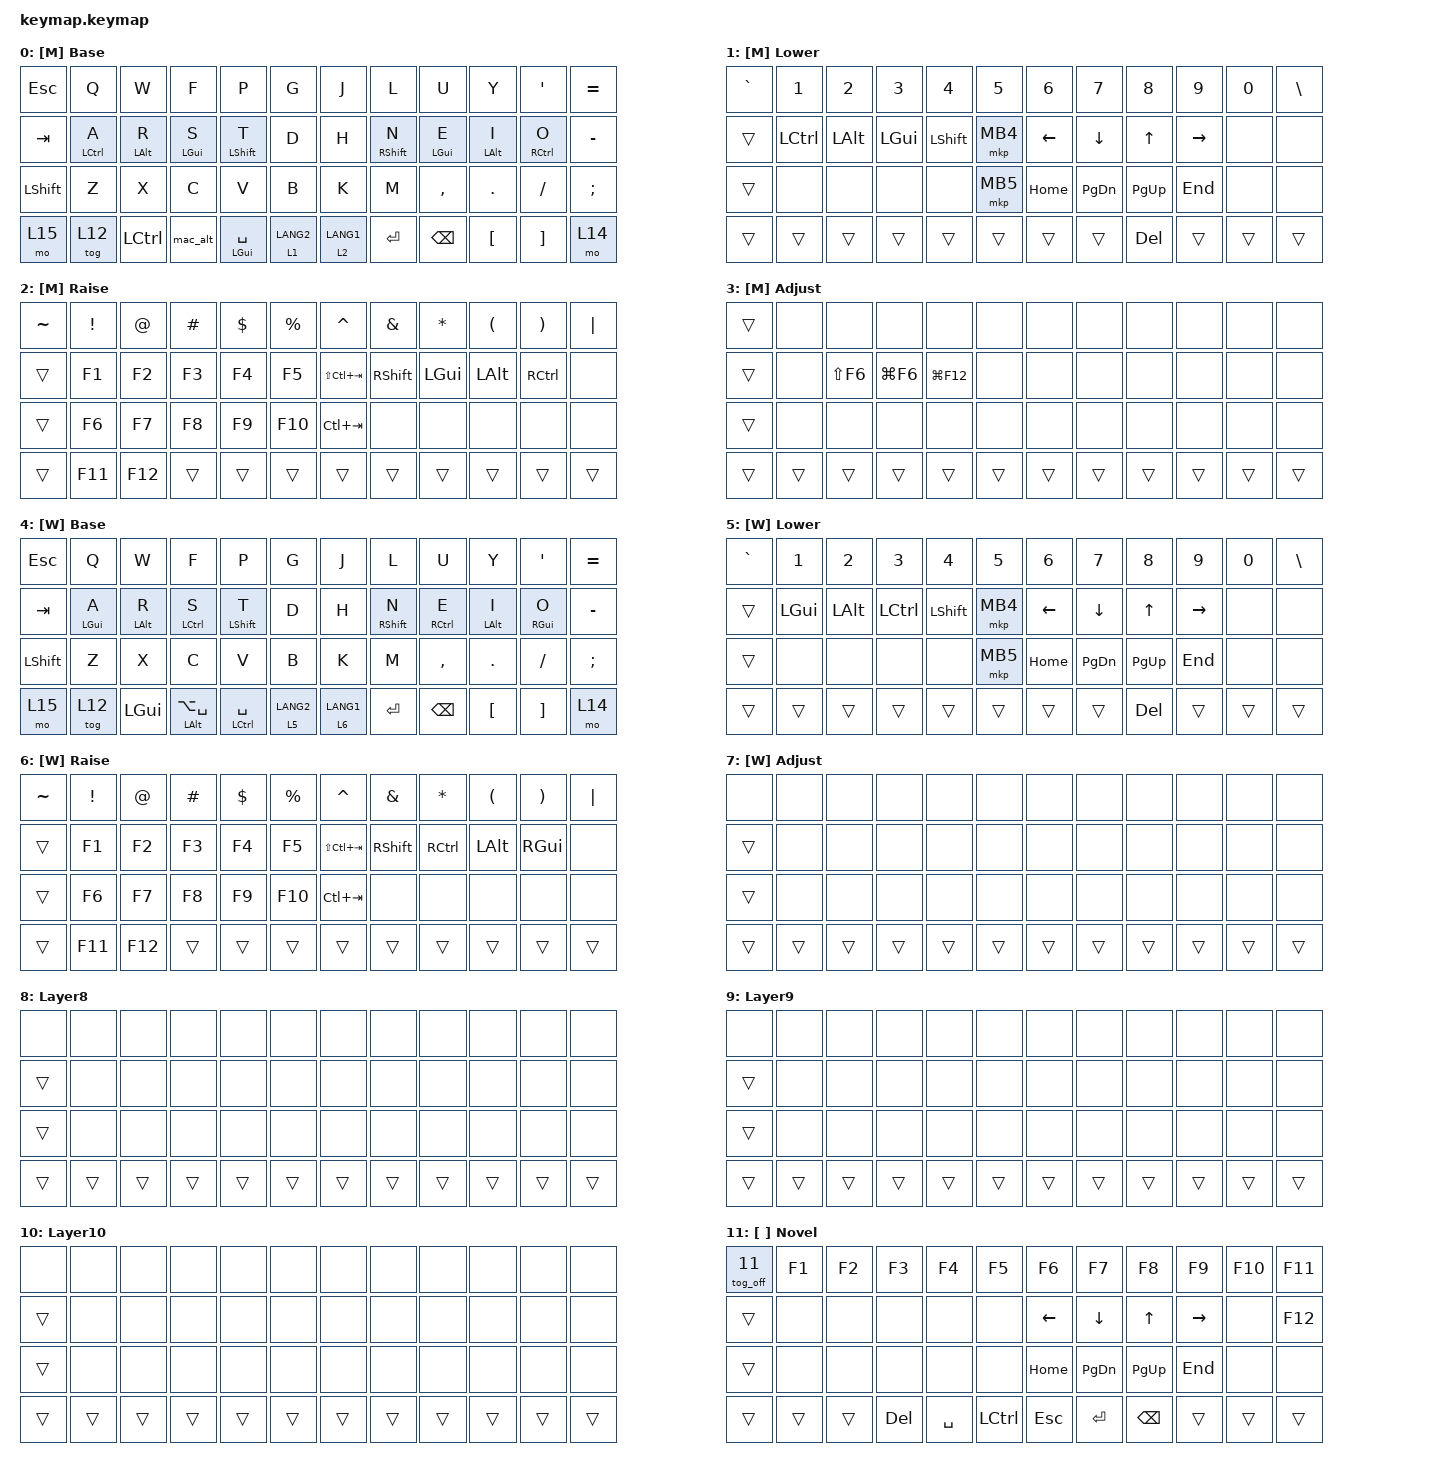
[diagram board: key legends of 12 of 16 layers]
#include <behaviors.dtsi>
#include <dt-bindings/zmk/bt.h>
#include <dt-bindings/zmk/keys.h>
#include <dt-bindings/zmk/outputs.h>
#include <dt-bindings/zmk/pointing.h>

&mt { tapping-term-ms = <180>; };

&lt { tapping-term-ms = <180>; };

&sl { release-after-ms = <2000>; };

/ {
    behaviors {
        hml: home_row_mod_left {
            compatible = "zmk,behavior-hold-tap";
            #binding-cells = <2>;
            flavor = "balanced";
            tapping-term-ms = <280>;
            require-prior-idle-ms = <150>;
            quick-tap-ms = <175>;
            hold-trigger-key-positions = <6 7 8 9 10 11 18 19 20 21 22 23 30 31 32 33 34 35 42 43 44 45 46 47>;
            hold-trigger-on-release;
            bindings = <&kp>, <&kp>;
        };

        hmr: home_row_mod_right {
            compatible = "zmk,behavior-hold-tap";
            #binding-cells = <2>;
            flavor = "balanced";
            tapping-term-ms = <280>;
            require-prior-idle-ms = <150>;
            quick-tap-ms = <175>;
            hold-trigger-key-positions = <0 1 2 3 4 5 12 13 14 15 16 17 24 25 26 27 28 29 36 37 38 39 40 41>;
            hold-trigger-on-release;
            bindings = <&kp>, <&kp>;
        };

        tog_on: tog_on {
            compatible = "zmk,behavior-toggle-layer";
            label = "TOG_ON";
            #binding-cells = <1>;
        };

        tog_off: tog_off {
            compatible = "zmk,behavior-toggle-layer";
            label = "TOG_OFF";
            #binding-cells = <1>;
            toggle-mode = "off";
        };

        mac_alt: mac_alt {
            compatible = "zmk,behavior-tap-dance";
            label = "MAC_ALT";
            #binding-cells = <0>;
            bindings = <&mt LALT LG(SPACE)>, <&kp LA(SPACE)>;

            tapping-term-ms = <180>;
        };
    };

    combos {
        compatible = "zmk,combos";

        boot {
            bindings = <&bootloader>;
            key-positions = <36 29>;
        };
    };

    macros {
        win_and_usb: win_and_usb {
            compatible = "zmk,behavior-macro";
            #binding-cells = <0>;
            bindings = <&tog_on 4 &out OUT_USB>;
            label = "WIN_AND_USB";
        };

        win_ble_4: win_ble_4 {
            compatible = "zmk,behavior-macro";
            #binding-cells = <0>;
            bindings = <&tog_on 4 &out OUT_BLE &bt BT_SEL 4>;
            label = "WIN_BLE_4";
        };

        mac_ble_0: mac_ble_0 {
            compatible = "zmk,behavior-macro";
            #binding-cells = <0>;
            bindings = <&tog_off 4 &out OUT_BLE &bt BT_SEL 0>;
            label = "MAC_BLE_0";
        };
    };

    keymap {
        compatible = "zmk,keymap";

        base_m {
            display-name = "[M]   Base";
            bindings = <
&kp ESC    &kp Q         &kp W        &kp F        &kp P           &kp G        &kp J        &kp L         &kp U        &kp Y        &kp APOS      &kp EQUAL
&kp TAB    &hml LCTRL A  &hml LALT R  &hml LGUI S  &hml LSHFT T    &kp D        &kp H        &hmr RSHFT N  &hmr LGUI E  &hmr LALT I  &hmr RCTRL O  &kp MINUS
&kp LSHFT  &kp Z         &kp X        &kp C        &kp V           &kp B        &kp K        &kp M         &kp COMMA    &kp DOT      &kp FSLH      &kp SEMI
&mo 15     &tog 12       &kp LCTRL    &mac_alt     &mt LGUI SPACE  &lt 1 LANG2  &lt 2 LANG1  &kp ENTER     &kp BSPC     &kp LBKT     &kp RBKT      &mo 14
            >;
        };

        lower_m {
            display-name = "[M] Lower";
            bindings = <
&kp GRAVE  &kp N1     &kp N2    &kp N3    &kp N4     &kp N5    &kp N6    &kp N7     &kp N8     &kp N9     &kp N0  &kp BSLH
&trans     &kp LCTRL  &kp LALT  &kp LGUI  &kp LSHFT  &mkp MB4  &kp LEFT  &kp DOWN   &kp UP     &kp RIGHT  &none   &none
&trans     &none      &none     &none     &none      &mkp MB5  &kp HOME  &kp PG_DN  &kp PG_UP  &kp END    &none   &none
&trans     &trans     &trans    &trans    &trans     &trans    &trans    &trans     &kp DEL    &trans     &trans  &trans
            >;
        };

        raise_m {
            display-name = "[M]  Raise";
            bindings = <
&kp TILDE  &kp EXCL  &kp AT   &kp HASH  &kp DLLR  &kp PRCNT  &kp CARET        &kp AMPS   &kp ASTRK  &kp LPAR  &kp RPAR   &kp PIPE
&trans     &kp F1    &kp F2   &kp F3    &kp F4    &kp F5     &kp LS(LC(TAB))  &kp RSHFT  &kp LGUI   &kp LALT  &kp RCTRL  &none
&trans     &kp F6    &kp F7   &kp F8    &kp F9    &kp F10    &kp LC(TAB)      &none      &none      &none     &none      &none
&trans     &kp F11   &kp F12  &trans    &trans    &trans     &trans           &trans     &trans     &trans    &trans     &trans
            >;
        };

        adjust_m {
            display-name = "[M] Adjust";
            bindings = <
&trans  &none   &none       &none       &none        &none   &none   &none   &none   &none   &none   &none
&trans  &none   &kp LS(F6)  &kp LG(F6)  &kp LG(F12)  &none   &none   &none   &none   &none   &none   &none
&trans  &none   &none       &none       &none        &none   &none   &none   &none   &none   &none   &none
&trans  &trans  &trans      &trans      &trans       &trans  &trans  &trans  &trans  &trans  &trans  &trans
            >;
        };

        base_w {
            display-name = "[W]   Base";
            bindings = <
&kp ESC    &kp Q        &kp W        &kp F               &kp P            &kp G        &kp J        &kp L         &kp U         &kp Y        &kp APOS     &kp EQUAL
&kp TAB    &hml LGUI A  &hml LALT R  &hml LCTRL S        &hml LSHFT T     &kp D        &kp H        &hmr RSHFT N  &hmr RCTRL E  &hmr LALT I  &hmr RGUI O  &kp MINUS
&kp LSHFT  &kp Z        &kp X        &kp C               &kp V            &kp B        &kp K        &kp M         &kp COMMA     &kp DOT      &kp FSLH     &kp SEMI
&mo 15     &tog 12      &kp LGUI     &mt LALT LA(SPACE)  &mt LCTRL SPACE  &lt 5 LANG2  &lt 6 LANG1  &kp ENTER     &kp BSPC      &kp LBKT     &kp RBKT     &mo 14
            >;
        };

        lower_w {
            display-name = "[W] Lower";
            bindings = <
&kp GRAVE  &kp N1    &kp N2    &kp N3     &kp N4     &kp N5    &kp N6    &kp N7     &kp N8     &kp N9     &kp N0  &kp BSLH
&trans     &kp LGUI  &kp LALT  &kp LCTRL  &kp LSHFT  &mkp MB4  &kp LEFT  &kp DOWN   &kp UP     &kp RIGHT  &none   &none
&trans     &none     &none     &none      &none      &mkp MB5  &kp HOME  &kp PG_DN  &kp PG_UP  &kp END    &none   &none
&trans     &trans    &trans    &trans     &trans     &trans    &trans    &trans     &kp DEL    &trans     &trans  &trans
            >;
        };

        raise_w {
            display-name = "[W]  Raise";
            bindings = <
&kp TILDE  &kp EXCL  &kp AT   &kp HASH  &kp DLLR  &kp PRCNT  &kp CARET        &kp AMPS   &kp ASTRK  &kp LPAR  &kp RPAR  &kp PIPE
&trans     &kp F1    &kp F2   &kp F3    &kp F4    &kp F5     &kp LS(LC(TAB))  &kp RSHFT  &kp RCTRL  &kp LALT  &kp RGUI  &none
&trans     &kp F6    &kp F7   &kp F8    &kp F9    &kp F10    &kp LC(TAB)      &none      &none      &none     &none     &none
&trans     &kp F11   &kp F12  &trans    &trans    &trans     &trans           &trans     &trans     &trans    &trans    &trans
            >;
        };

        adjust_w {
            display-name = "[W] Adjust";
            bindings = <
&none   &none   &none   &none   &none   &none   &none   &none   &none   &none   &none   &none
&trans  &none   &none   &none   &none   &none   &none   &none   &none   &none   &none   &none
&trans  &none   &none   &none   &none   &none   &none   &none   &none   &none   &none   &none
&trans  &trans  &trans  &trans  &trans  &trans  &trans  &trans  &trans  &trans  &trans  &trans
            >;
        };

        layer_8 {
            display-name = "Layer8";
            bindings = <
&none   &none   &none   &none   &none   &none   &none   &none   &none   &none   &none   &none
&trans  &none   &none   &none   &none   &none   &none   &none   &none   &none   &none   &none
&trans  &none   &none   &none   &none   &none   &none   &none   &none   &none   &none   &none
&trans  &trans  &trans  &trans  &trans  &trans  &trans  &trans  &trans  &trans  &trans  &trans
            >;
        };

        layer_9 {
            display-name = "Layer9";
            bindings = <
&none   &none   &none   &none   &none   &none   &none   &none   &none   &none   &none   &none
&trans  &none   &none   &none   &none   &none   &none   &none   &none   &none   &none   &none
&trans  &none   &none   &none   &none   &none   &none   &none   &none   &none   &none   &none
&trans  &trans  &trans  &trans  &trans  &trans  &trans  &trans  &trans  &trans  &trans  &trans
            >;
        };

        layer_10 {
            display-name = "Layer10";
            bindings = <
&none   &none   &none   &none   &none   &none   &none   &none   &none   &none   &none   &none
&trans  &none   &none   &none   &none   &none   &none   &none   &none   &none   &none   &none
&trans  &none   &none   &none   &none   &none   &none   &none   &none   &none   &none   &none
&trans  &trans  &trans  &trans  &trans  &trans  &trans  &trans  &trans  &trans  &trans  &trans
            >;
        };

        novel {
            display-name = "[ ]  Novel";
            bindings = <
&tog_off 11  &kp F1  &kp F2  &kp F3   &kp F4     &kp F5     &kp F6    &kp F7     &kp F8     &kp F9     &kp F10  &kp F11
&trans       &none   &none   &none    &none      &none      &kp LEFT  &kp DOWN   &kp UP     &kp RIGHT  &none    &kp F12
&trans       &none   &none   &none    &none      &none      &kp HOME  &kp PG_DN  &kp PG_UP  &kp END    &none    &none
&trans       &trans  &trans  &kp DEL  &kp SPACE  &kp LCTRL  &kp ESC   &kp ENTER  &kp BSPC   &trans     &trans   &trans
            >;
        };

        navigation {
            display-name = "[ ]   Navi";
            bindings = <
&tog_off 12  &none   &none           &mmv MOVE_UP    &none            &none   &none     &none      &none      &none      &none   &none
&trans       &none   &mmv MOVE_LEFT  &mmv MOVE_DOWN  &mmv MOVE_RIGHT  &none   &mkp MB4  &mkp LCLK  &mkp MCLK  &mkp RCLK  &none   &none
&trans       &none   &none           &none           &none            &none   &mkp MB5  &none      &none      &none      &none   &none
&trans       &trans  &trans          &trans          &trans           &trans  &trans    &trans     &trans     &trans     &trans  &trans
            >;
        };

        key_pad {
            display-name = "[ ] KeyPad";
            bindings = <
&tog_off 13  &none   &none   &none   &none   &none   &none   &none      &kp EQUAL  &kp N7  &kp N8   &kp N9
&trans       &none   &none   &none   &none   &none   &none   &kp MINUS  &kp PLUS   &kp N4  &kp N5   &kp N6
&trans       &none   &none   &none   &none   &none   &none   &kp SLASH  &kp STAR   &kp N1  &kp N2   &kp N3
&trans       &trans  &trans  &trans  &trans  &trans  &trans  &trans     &trans     &kp N0  &kp DOT  &kp EQUAL
            >;
        };

        device {
            display-name = "[ ] Device";
            bindings = <
&none           &kp C_BRI_DN  &kp C_BRI_UP  &none   &none   &none   &kp C_PREV    &kp C_PP      &kp C_NEXT    &kp C_MUTE    &kp C_VOL_DN  &kp C_VOL_UP
&trans          &none         &none         &none   &none   &none   &win_and_usb  &mac_ble_0    &none         &none         &none         &win_ble_4
&trans          &none         &none         &none   &none   &none   &out OUT_TOG  &bt BT_SEL 0  &bt BT_SEL 1  &bt BT_SEL 2  &bt BT_SEL 3  &bt BT_SEL 4
&bt BT_CLR_ALL  &trans        &trans        &trans  &trans  &trans  &trans        &trans        &trans        &trans        &bt BT_CLR    &trans
            >;
        };

        mode {
            display-name = "[ ]   Mode";
            bindings = <
&none   &none   &tog 4  &none   &none   &tog_on 11  &none   &none       &none   &none   &none   &none
&trans  &none   &none   &none   &none   &none       &none   &tog_on 12  &none   &none   &none   &none
&trans  &none   &none   &none   &none   &none       &none   &none       &none   &none   &none   &none
&trans  &trans  &trans  &trans  &trans  &trans      &trans  &trans      &trans  &trans  &trans  &trans
            >;
        };
    };

    conditional_layers {
        compatible = "zmk,conditional-layers";

        adjust_mac {
            if-layers = <1 2>;
            then-layer = <3>;
        };

        win_adjust {
            if-layers = <5 6>;
            then-layer = <7>;
        };
    };
};
